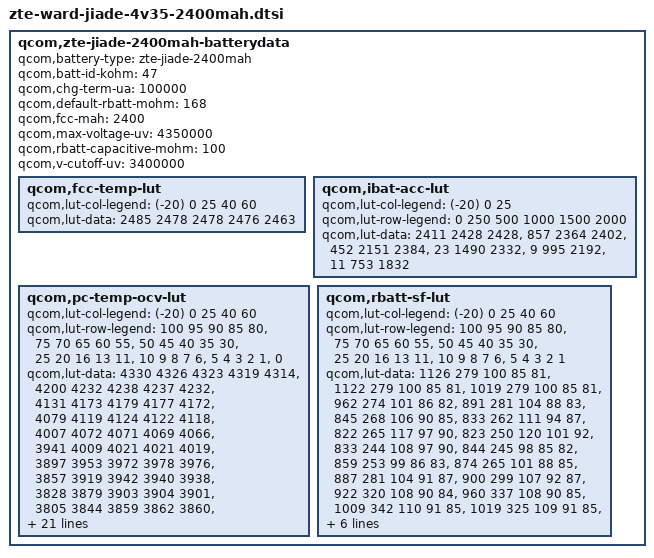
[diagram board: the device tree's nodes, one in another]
/* Copyright (c) 2014, The Linux Foundation. All rights reserved.
*
* This program is free software; you can redistribute it and/or modify
* it under the terms of the GNU General Public License version 2 and
* only version 2 as published by the Free Software Foundation.
*
* This program is distributed in the hope that it will be useful,
* but WITHOUT ANY WARRANTY; without even the implied warranty of
* MERCHANTABILITY or FITNESS FOR A PARTICULAR PURPOSE.  See the
* GNU General Public License for more details.
*/

qcom,zte-jiade-2400mah-batterydata {
	qcom,battery-type = "zte-jiade-2400mah";
	qcom,batt-id-kohm = <47>;
	qcom,chg-term-ua = <100000>;
	qcom,default-rbatt-mohm = <168>;
	qcom,fcc-mah = <2400>;
	qcom,max-voltage-uv = <4350000>;
	qcom,rbatt-capacitive-mohm = <100>;
	qcom,v-cutoff-uv = <3400000>;

	qcom,fcc-temp-lut {
		qcom,lut-col-legend = <(-20) 0 25 40 60>;
		qcom,lut-data = <2485 2478 2478 2476 2463>;
	};

	qcom,ibat-acc-lut {
		qcom,lut-col-legend = <(-20) 0 25>;
		qcom,lut-row-legend = <0 250 500 1000 1500 2000>;
		qcom,lut-data = <2411 2428 2428>,
				<857 2364 2402>,
				<452 2151 2384>,
				<23 1490 2332>,
				<9 995 2192>,
				<11 753 1832>;
	};

	qcom,pc-temp-ocv-lut {
		qcom,lut-col-legend = <(-20) 0 25 40 60>;
		qcom,lut-row-legend = <100 95 90 85 80>,
					<75 70 65 60 55>,
					<50 45 40 35 30>,
					<25 20 16 13 11>,
					<10 9 8 7 6>,
					<5 4 3 2 1>,
					<0>;
		qcom,lut-data = <4330 4326 4323 4319 4314>,
				<4200 4232 4238 4237 4232>,
				<4131 4173 4179 4177 4172>,
				<4079 4119 4124 4122 4118>,
				<4007 4072 4071 4069 4066>,
				<3941 4009 4021 4021 4019>,
				<3897 3953 3972 3978 3976>,
				<3857 3919 3942 3940 3938>,
				<3828 3879 3903 3904 3901>,
				<3805 3844 3859 3862 3860>,
				<3785 3817 3824 3824 3823>,
				<3767 3798 3803 3803 3801>,
				<3748 3786 3788 3787 3785>,
				<3726 3777 3777 3776 3773>,
				<3701 3770 3770 3766 3759>,
				<3677 3762 3760 3751 3738>,
				<3655 3746 3743 3734 3719>,
				<3637 3725 3722 3713 3699>,
				<3624 3702 3701 3693 3680>,
				<3611 3687 3688 3682 3670>,
				<3603 3681 3686 3680 3669>,
				<3595 3677 3684 3679 3668>,
				<3584 3671 3681 3676 3666>,
				<3571 3664 3678 3673 3662>,
				<3553 3654 3671 3666 3652>,
				<3527 3633 3652 3642 3624>,
				<3489 3584 3597 3593 3574>,
				<3436 3494 3516 3520 3502>,
				<3358 3395 3408 3417 3402>,
				<3232 3266 3269 3260 3260>,
				<3000 3000 3000 3000 3000>;
	};

	qcom,rbatt-sf-lut {
		qcom,lut-col-legend = <(-20) 0 25 40 60>;
		qcom,lut-row-legend = <100 95 90 85 80>,
					<75 70 65 60 55>,
					<50 45 40 35 30>,
					<25 20 16 13 11>,
					<10 9 8 7 6>,
					<5 4 3 2 1>;
		qcom,lut-data = <1126 279 100 85 81>,
				<1122 279 100 85 81>,
				<1019 279 100 85 81>,
				<962 274 101 86 82>,
				<891 281 104 88 83>,
				<845 268 106 90 85>,
				<833 262 111 94 87>,
				<822 265 117 97 90>,
				<823 250 120 101 92>,
				<833 244 108 97 90>,
				<844 245 98 85 82>,
				<859 253 99 86 83>,
				<874 265 101 88 85>,
				<887 281 104 91 87>,
				<900 299 107 92 87>,
				<922 320 108 90 84>,
				<960 337 108 90 85>,
				<1009 342 110 91 85>,
				<1019 325 109 91 85>,
				<1070 333 108 90 84>,
				<1101 342 110 91 85>,
				<1134 355 115 93 87>,
				<1171 369 119 96 88>,
				<1215 385 126 99 89>,
				<1288 404 133 101 89>,
				<1453 420 138 101 88>,
				<1737 416 143 106 90>,
				<2209 422 147 112 96>,
				<3055 458 144 113 103>,
				<4894 554 156 124 109>;
	};
};
